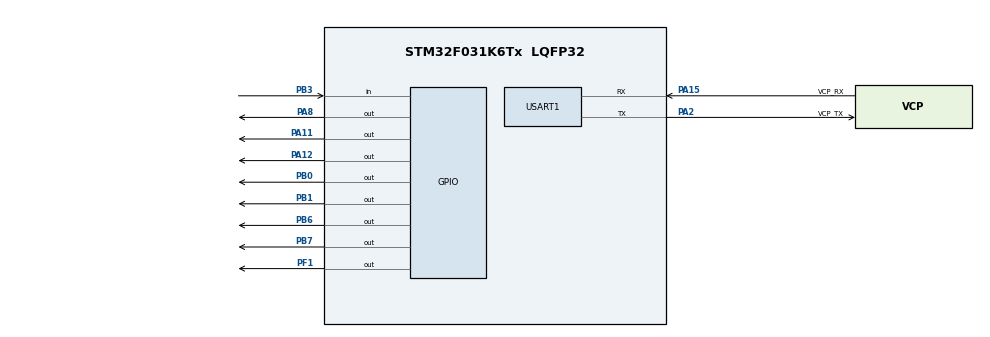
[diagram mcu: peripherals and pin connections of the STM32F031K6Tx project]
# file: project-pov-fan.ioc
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Mcu.Family=STM32F0
Mcu.Name=STM32F031K6Tx
Mcu.Package=LQFP32
PA11.Signal=GPIO_Output
PA12.Signal=GPIO_Output
PA13.GPIO_Label=SWDIO
PA13.Mode=Serial_Wire
PA13.Signal=SYS_SWDIO
PA14.GPIO_Label=SWCLK
PA14.Mode=Serial_Wire
PA14.Signal=SYS_SWCLK
PA15.GPIO_Label=VCP_RX
PA15.Mode=Asynchronous
PA15.Signal=USART1_RX
PA2.GPIO_Label=VCP_TX
PA2.Mode=Asynchronous
PA2.Signal=USART1_TX
PA8.Signal=GPIO_Output
PB0.Signal=GPIO_Output
PB1.Signal=GPIO_Output
PB3.Signal=GPIO_Input
PB6.Signal=GPIO_Output
PB7.Signal=GPIO_Output
PF0-OSC_IN.Mode=HSE-External-Clock-Source
PF0-OSC_IN.Signal=RCC_OSC_IN
PF1-OSC_OUT.Signal=GPIO_Output
ProjectManager.HeapSize=0x200
ProjectManager.StackSize=0x400
ProjectManager.TargetToolchain=STM32CubeIDE
USART1.VirtualMode-Asynchronous=VM_ASYNC
board=NUCLEO-F031K6

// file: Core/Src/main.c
/* USER CODE BEGIN Header */
/**
  ******************************************************************************
  * @file           : main.c
  * @brief          : Main program body
  ******************************************************************************
  * @attention
  *
  * Copyright (c) 2021 STMicroelectronics.
  * All rights reserved.
  *
  * This software is licensed under terms that can be found in the LICENSE file
  * in the root directory of this software component.
  * If no LICENSE file comes with this software, it is provided AS-IS.
  *
  ******************************************************************************
  */
/* USER CODE END Header */
#include "main.h"
#include "characters.h"

UART_HandleTypeDef huart1;

void SystemClock_Config(void);
static void MX_GPIO_Init(void);
static void MX_USART1_UART_Init(void);
void printLetter(int []);
void loop(void);

int main(void)
{

  /* MCU Configuration--------------------------------------------------------*/

  /* Reset of all peripherals, Initializes the Flash interface and the Systick. */
  HAL_Init();

  /* Configure the system clock */
  SystemClock_Config();

  /* Initialize all configured peripherals */
  MX_GPIO_Init();
  MX_USART1_UART_Init();

  /* Infinite loop */
  while (1)
  {

    /* USER CODE BEGIN 3 */
	  loop();
  }
  /* USER CODE END 3 */
}

void SystemClock_Config(void)
{
  RCC_OscInitTypeDef RCC_OscInitStruct = {0};
  RCC_ClkInitTypeDef RCC_ClkInitStruct = {0};
  RCC_PeriphCLKInitTypeDef PeriphClkInit = {0};

  /** Initializes the RCC Oscillators according to the specified parameters
  * in the RCC_OscInitTypeDef structure.
  */
  RCC_OscInitStruct.OscillatorType = RCC_OSCILLATORTYPE_HSI;
  RCC_OscInitStruct.HSIState = RCC_HSI_ON;
  RCC_OscInitStruct.HSICalibrationValue = RCC_HSICALIBRATION_DEFAULT;
  RCC_OscInitStruct.PLL.PLLState = RCC_PLL_NONE;
  if (HAL_RCC_OscConfig(&RCC_OscInitStruct) != HAL_OK)
  {
    Error_Handler();
  }
  /** Initializes the CPU, AHB and APB buses clocks
  */
  RCC_ClkInitStruct.ClockType = RCC_CLOCKTYPE_HCLK|RCC_CLOCKTYPE_SYSCLK
                              |RCC_CLOCKTYPE_PCLK1;
  RCC_ClkInitStruct.SYSCLKSource = RCC_SYSCLKSOURCE_HSI;
  RCC_ClkInitStruct.AHBCLKDivider = RCC_SYSCLK_DIV1;
  RCC_ClkInitStruct.APB1CLKDivider = RCC_HCLK_DIV1;

  if (HAL_RCC_ClockConfig(&RCC_ClkInitStruct, FLASH_LATENCY_0) != HAL_OK)
  {
    Error_Handler();
  }
  PeriphClkInit.PeriphClockSelection = RCC_PERIPHCLK_USART1;
  PeriphClkInit.Usart1ClockSelection = RCC_USART1CLKSOURCE_PCLK1;
  if (HAL_RCCEx_PeriphCLKConfig(&PeriphClkInit) != HAL_OK)
  {
    Error_Handler();
  }
}

static void MX_USART1_UART_Init(void)
{

  huart1.Instance = USART1;
  huart1.Init.BaudRate = 38400;
  huart1.Init.WordLength = UART_WORDLENGTH_8B;
  huart1.Init.StopBits = UART_STOPBITS_1;
  huart1.Init.Parity = UART_PARITY_NONE;
  huart1.Init.Mode = UART_MODE_TX_RX;
  huart1.Init.HwFlowCtl = UART_HWCONTROL_NONE;
  huart1.Init.OverSampling = UART_OVERSAMPLING_16;
  huart1.Init.OneBitSampling = UART_ONE_BIT_SAMPLE_DISABLE;
  huart1.AdvancedInit.AdvFeatureInit = UART_ADVFEATURE_NO_INIT;
  if (HAL_UART_Init(&huart1) != HAL_OK)
  {
    Error_Handler();
  }

}

static void MX_GPIO_Init(void)
{
  GPIO_InitTypeDef GPIO_InitStruct = {0};

  /* GPIO Ports Clock Enable */
  __HAL_RCC_GPIOF_CLK_ENABLE();
  __HAL_RCC_GPIOA_CLK_ENABLE();
  __HAL_RCC_GPIOB_CLK_ENABLE();

  /*Configure GPIO pin Output Level */
  HAL_GPIO_WritePin(GPIOF, GPIO_PIN_1, GPIO_PIN_RESET);

  /*Configure GPIO pin Output Level */
  HAL_GPIO_WritePin(GPIOB, GPIO_PIN_0|GPIO_PIN_1|GPIO_PIN_6|GPIO_PIN_7, GPIO_PIN_RESET);

  /*Configure GPIO pin Output Level */
  HAL_GPIO_WritePin(GPIOA, GPIO_PIN_8|GPIO_PIN_11|GPIO_PIN_12, GPIO_PIN_RESET);

  /*Configure GPIO pin : PF1 */
  GPIO_InitStruct.Pin = GPIO_PIN_1;
  GPIO_InitStruct.Mode = GPIO_MODE_OUTPUT_PP;
  GPIO_InitStruct.Pull = GPIO_NOPULL;
  GPIO_InitStruct.Speed = GPIO_SPEED_FREQ_LOW;
  HAL_GPIO_Init(GPIOF, &GPIO_InitStruct);

  /*Configure GPIO pins : PB0 PB1 PB6 PB7 */
  GPIO_InitStruct.Pin = GPIO_PIN_0|GPIO_PIN_1|GPIO_PIN_6|GPIO_PIN_7;
  GPIO_InitStruct.Mode = GPIO_MODE_OUTPUT_PP;
  GPIO_InitStruct.Pull = GPIO_NOPULL;
  GPIO_InitStruct.Speed = GPIO_SPEED_FREQ_LOW;
  HAL_GPIO_Init(GPIOB, &GPIO_InitStruct);

  /*Configure GPIO pins : PA8 PA11 PA12 */
  GPIO_InitStruct.Pin = GPIO_PIN_8|GPIO_PIN_11|GPIO_PIN_12;
  GPIO_InitStruct.Mode = GPIO_MODE_OUTPUT_PP;
  GPIO_InitStruct.Pull = GPIO_NOPULL;
  GPIO_InitStruct.Speed = GPIO_SPEED_FREQ_LOW;
  HAL_GPIO_Init(GPIOA, &GPIO_InitStruct);

  /*Configure GPIO pin : PB3 */
  GPIO_InitStruct.Pin = GPIO_PIN_3;
  GPIO_InitStruct.Mode = GPIO_MODE_INPUT;
  GPIO_InitStruct.Pull = GPIO_NOPULL;
  HAL_GPIO_Init(GPIOB, &GPIO_InitStruct);

}

void Error_Handler(void)
{
  __disable_irq();
  while (1)
  {
  }
}
void printLetter(int letter[])
 {
 int y;
 // printing the first y row of the letter
 for (y=0; y<8; y++)
 {
	 if(letter[y]){
		 switch(y % 8)
		 	 {
		 	 case 0:
		 		 HAL_GPIO_WritePin(GPIOA, GPIO_PIN_12, GPIO_PIN_SET);
		 		 break;
		 	 case 1:
		 		 HAL_GPIO_WritePin(GPIOB, GPIO_PIN_0, GPIO_PIN_SET);
		 		 break;
		 	 case 2:
		 		 HAL_GPIO_WritePin(GPIOB, GPIO_PIN_7, GPIO_PIN_SET);
		 		 break;
		 	 case 3:
		 		 HAL_GPIO_WritePin(GPIOB, GPIO_PIN_6, GPIO_PIN_SET);
		 		 break;
		 	 case 4:
		 		 HAL_GPIO_WritePin(GPIOB, GPIO_PIN_1, GPIO_PIN_SET);
		 		 break;
		 	 case 5:
		 		 HAL_GPIO_WritePin(GPIOF, GPIO_PIN_1, GPIO_PIN_SET);
		 		 break;
		 	 case 6:
		 		 HAL_GPIO_WritePin(GPIOA, GPIO_PIN_8, GPIO_PIN_SET);
		 		 break;
		 	 case 7:
		 		 HAL_GPIO_WritePin(GPIOF, GPIO_PIN_11, GPIO_PIN_SET);
		 		 break;
		 	 }
	 }
	 else if(!letter[y]){
		 switch(y % 8)
		 	 {
		 	 case 0:
		 		 HAL_GPIO_WritePin(GPIOA, GPIO_PIN_12, GPIO_PIN_RESET);
		 		 break;
		 	 case 1:
		 		 HAL_GPIO_WritePin(GPIOB, GPIO_PIN_0, GPIO_PIN_RESET);
		 		 break;
		 	 case 2:
		 		 HAL_GPIO_WritePin(GPIOB, GPIO_PIN_7, GPIO_PIN_RESET);
		 		 break;
		 	 case 3:
		 		 HAL_GPIO_WritePin(GPIOB, GPIO_PIN_6, GPIO_PIN_RESET);
		 		 break;
		 	 case 4:
		 		 HAL_GPIO_WritePin(GPIOB, GPIO_PIN_1, GPIO_PIN_RESET);
		 		 break;
		 	 case 5:
		 		 HAL_GPIO_WritePin(GPIOF, GPIO_PIN_1, GPIO_PIN_RESET);
		 		 break;
		 	 case 6:
		 		 HAL_GPIO_WritePin(GPIOA, GPIO_PIN_8, GPIO_PIN_RESET);
		 		 break;
		 	 case 7:
		 		 HAL_GPIO_WritePin(GPIOF, GPIO_PIN_11, GPIO_PIN_RESET);
		 		 break;
		 	 }
	 }
 }
 HAL_Delay(dotTime);
// printing the second y row of the letter
 for (y=0; y<8; y++)
 {
	 if(letter[y + 8]){
		 switch(y % 8)
		 	 {
		 	 case 0:
		 		 HAL_GPIO_WritePin(GPIOA, GPIO_PIN_12, GPIO_PIN_SET);
		 		 break;
		 	 case 1:
		 		 HAL_GPIO_WritePin(GPIOB, GPIO_PIN_0, GPIO_PIN_SET);
		 		 break;
		 	 case 2:
		 		 HAL_GPIO_WritePin(GPIOB, GPIO_PIN_7, GPIO_PIN_SET);
		 		 break;
		 	 case 3:
		 		 HAL_GPIO_WritePin(GPIOB, GPIO_PIN_6, GPIO_PIN_SET);
		 		 break;
		 	 case 4:
		 		 HAL_GPIO_WritePin(GPIOB, GPIO_PIN_1, GPIO_PIN_SET);
		 		 break;
		 	 case 5:
		 		 HAL_GPIO_WritePin(GPIOF, GPIO_PIN_1, GPIO_PIN_SET);
		 		 break;
		 	 case 6:
		 		 HAL_GPIO_WritePin(GPIOA, GPIO_PIN_8, GPIO_PIN_SET);
		 		 break;
		 	 case 7:
		 		 HAL_GPIO_WritePin(GPIOF, GPIO_PIN_11, GPIO_PIN_SET);
		 		 break;
		 	 }
	 }
	 else if(!letter[y + 8]){
		 switch(y % 8)
		 	 {
		 	 case 0:
		 		 HAL_GPIO_WritePin(GPIOA, GPIO_PIN_12, GPIO_PIN_RESET);
		 		 break;
		 	 case 1:
		 		 HAL_GPIO_WritePin(GPIOB, GPIO_PIN_0, GPIO_PIN_RESET);
		 		 break;
		 	 case 2:
		 		 HAL_GPIO_WritePin(GPIOB, GPIO_PIN_7, GPIO_PIN_RESET);
		 		 break;
		 	 case 3:
		 		 HAL_GPIO_WritePin(GPIOB, GPIO_PIN_6, GPIO_PIN_RESET);
		 		 break;
		 	 case 4:
		 		 HAL_GPIO_WritePin(GPIOB, GPIO_PIN_1, GPIO_PIN_RESET);
		 		 break;
		 	 case 5:
		 		 HAL_GPIO_WritePin(GPIOF, GPIO_PIN_1, GPIO_PIN_RESET);
		 		 break;
		 	 case 6:
		 		 HAL_GPIO_WritePin(GPIOA, GPIO_PIN_8, GPIO_PIN_RESET);
		 		 break;
		 	 case 7:
		 		 HAL_GPIO_WritePin(GPIOF, GPIO_PIN_11, GPIO_PIN_RESET);
		 		 break;
		 	 }
	 }
 }
    HAL_Delay(dotTime);
// printing the third y row of the letter
 for (y=0; y<8; y++)
 {
	 if(letter[y + 16]){
		 switch(y % 8)
		 	 {
		 	 case 0:
		 		 HAL_GPIO_WritePin(GPIOA, GPIO_PIN_12, GPIO_PIN_SET);
		 		 break;
		 	 case 1:
		 		 HAL_GPIO_WritePin(GPIOB, GPIO_PIN_0, GPIO_PIN_SET);
		 		 break;
		 	 case 2:
		 		 HAL_GPIO_WritePin(GPIOB, GPIO_PIN_7, GPIO_PIN_SET);
		 		 break;
		 	 case 3:
		 		 HAL_GPIO_WritePin(GPIOB, GPIO_PIN_6, GPIO_PIN_SET);
		 		 break;
		 	 case 4:
		 		 HAL_GPIO_WritePin(GPIOB, GPIO_PIN_1, GPIO_PIN_SET);
		 		 break;
		 	 case 5:
		 		 HAL_GPIO_WritePin(GPIOF, GPIO_PIN_1, GPIO_PIN_SET);
		 		 break;
		 	 case 6:
		 		 HAL_GPIO_WritePin(GPIOA, GPIO_PIN_8, GPIO_PIN_SET);
		 		 break;
		 	 case 7:
		 		 HAL_GPIO_WritePin(GPIOF, GPIO_PIN_11, GPIO_PIN_SET);
		 		 break;
		 	 }
	 }
	 else if(!letter[y + 16]){
		 switch(y % 8)
		 	 {
		 	 case 0:
		 		 HAL_GPIO_WritePin(GPIOA, GPIO_PIN_12, GPIO_PIN_RESET);
		 		 break;
		 	 case 1:
		 		 HAL_GPIO_WritePin(GPIOB, GPIO_PIN_0, GPIO_PIN_RESET);
		 		 break;
		 	 case 2:
		 		 HAL_GPIO_WritePin(GPIOB, GPIO_PIN_7, GPIO_PIN_RESET);
		 		 break;
		 	 case 3:
		 		 HAL_GPIO_WritePin(GPIOB, GPIO_PIN_6, GPIO_PIN_RESET);
		 		 break;
		 	 case 4:
		 		 HAL_GPIO_WritePin(GPIOB, GPIO_PIN_1, GPIO_PIN_RESET);
		 		 break;
		 	 case 5:
		 		 HAL_GPIO_WritePin(GPIOF, GPIO_PIN_1, GPIO_PIN_RESET);
		 		 break;
		 	 case 6:
		 		 HAL_GPIO_WritePin(GPIOA, GPIO_PIN_8, GPIO_PIN_RESET);
		 		 break;
		 	 case 7:
		 		 HAL_GPIO_WritePin(GPIOF, GPIO_PIN_11, GPIO_PIN_RESET);
		 		 break;
		 	 }
	 }
 }
    HAL_Delay(dotTime);
 for(y = 0; y<8; y++)
    {
	 if(letter[y + 24]){
		 switch(y % 8)
		 	 {
		 	 case 0:
		 		 HAL_GPIO_WritePin(GPIOA, GPIO_PIN_12, GPIO_PIN_SET);
		 		 break;
		 	 case 1:
		 		 HAL_GPIO_WritePin(GPIOB, GPIO_PIN_0, GPIO_PIN_SET);
		 		 break;
		 	 case 2:
		 		 HAL_GPIO_WritePin(GPIOB, GPIO_PIN_7, GPIO_PIN_SET);
		 		 break;
		 	 case 3:
		 		 HAL_GPIO_WritePin(GPIOB, GPIO_PIN_6, GPIO_PIN_SET);
		 		 break;
		 	 case 4:
		 		 HAL_GPIO_WritePin(GPIOB, GPIO_PIN_1, GPIO_PIN_SET);
		 		 break;
		 	 case 5:
		 		 HAL_GPIO_WritePin(GPIOF, GPIO_PIN_1, GPIO_PIN_SET);
		 		 break;
		 	 case 6:
		 		 HAL_GPIO_WritePin(GPIOA, GPIO_PIN_8, GPIO_PIN_SET);
		 		 break;
		 	 case 7:
		 		 HAL_GPIO_WritePin(GPIOF, GPIO_PIN_11, GPIO_PIN_SET);
		 		 break;
		 	 }
	 }
	 else if(!letter[y + 24]){
		 switch(y % 8)
		 	 {
		 	 case 0:
		 		 HAL_GPIO_WritePin(GPIOA, GPIO_PIN_12, GPIO_PIN_RESET);
		 		 break;
		 	 case 1:
		 		 HAL_GPIO_WritePin(GPIOB, GPIO_PIN_0, GPIO_PIN_RESET);
		 		 break;
		 	 case 2:
		 		 HAL_GPIO_WritePin(GPIOB, GPIO_PIN_7, GPIO_PIN_RESET);
		 		 break;
		 	 case 3:
		 		 HAL_GPIO_WritePin(GPIOB, GPIO_PIN_6, GPIO_PIN_RESET);
		 		 break;
		 	 case 4:
		 		 HAL_GPIO_WritePin(GPIOB, GPIO_PIN_1, GPIO_PIN_RESET);
		 		 break;
		 	 case 5:
		 		 HAL_GPIO_WritePin(GPIOF, GPIO_PIN_1, GPIO_PIN_RESET);
		 		 break;
		 	 case 6:
		 		 HAL_GPIO_WritePin(GPIOA, GPIO_PIN_8, GPIO_PIN_RESET);
		 		 break;
		 	 case 7:
		 		 HAL_GPIO_WritePin(GPIOF, GPIO_PIN_11, GPIO_PIN_RESET);
		 		 break;
		 	 }
	 }
    }
 	 HAL_Delay(dotTime);
for(y = 0; y<8; y++)
    {
	 if(letter[y + 32]){
		 switch(y % 8)
		 	 {
		 	 case 0:
		 		 HAL_GPIO_WritePin(GPIOA, GPIO_PIN_12, GPIO_PIN_SET);
		 		 break;
		 	 case 1:
		 		 HAL_GPIO_WritePin(GPIOB, GPIO_PIN_0, GPIO_PIN_SET);
		 		 break;
		 	 case 2:
		 		 HAL_GPIO_WritePin(GPIOB, GPIO_PIN_7, GPIO_PIN_SET);
		 		 break;
		 	 case 3:
		 		 HAL_GPIO_WritePin(GPIOB, GPIO_PIN_6, GPIO_PIN_SET);
		 		 break;
		 	 case 4:
		 		 HAL_GPIO_WritePin(GPIOB, GPIO_PIN_1, GPIO_PIN_SET);
		 		 break;
		 	 case 5:
		 		 HAL_GPIO_WritePin(GPIOF, GPIO_PIN_1, GPIO_PIN_SET);
		 		 break;
		 	 case 6:
		 		 HAL_GPIO_WritePin(GPIOA, GPIO_PIN_8, GPIO_PIN_SET);
		 		 break;
		 	 case 7:
		 		 HAL_GPIO_WritePin(GPIOF, GPIO_PIN_11, GPIO_PIN_SET);
		 		 break;
		 	 }
	 }
	 else if(!letter[y + 32]){
		 switch(y % 8)
		 	 {
		 	 case 0:
		 		 HAL_GPIO_WritePin(GPIOA, GPIO_PIN_12, GPIO_PIN_RESET);
		 		 break;
		 	 case 1:
		 		 HAL_GPIO_WritePin(GPIOB, GPIO_PIN_0, GPIO_PIN_RESET);
		 		 break;
		 	 case 2:
		 		 HAL_GPIO_WritePin(GPIOB, GPIO_PIN_7, GPIO_PIN_RESET);
		 		 break;
		 	 case 3:
		 		 HAL_GPIO_WritePin(GPIOB, GPIO_PIN_6, GPIO_PIN_RESET);
		 		 break;
		 	 case 4:
		 		 HAL_GPIO_WritePin(GPIOB, GPIO_PIN_1, GPIO_PIN_RESET);
		 		 break;
		 	 case 5:
		 		 HAL_GPIO_WritePin(GPIOF, GPIO_PIN_1, GPIO_PIN_RESET);
		 		 break;
		 	 case 6:
		 		 HAL_GPIO_WritePin(GPIOA, GPIO_PIN_8, GPIO_PIN_RESET);
		 		 break;
		 	 case 7:
		 		 HAL_GPIO_WritePin(GPIOF, GPIO_PIN_11, GPIO_PIN_RESET);
		 		 break;
		 	 }
	 }
    }
  	  HAL_Delay(dotTime);
 // printing the space between the letters
 for (y=0; y<8; y++)
 {
	 HAL_GPIO_WritePin(GPIOA, GPIO_PIN_12, GPIO_PIN_RESET);
	 HAL_GPIO_WritePin(GPIOB, GPIO_PIN_0, GPIO_PIN_RESET);
	 HAL_GPIO_WritePin(GPIOB, GPIO_PIN_7, GPIO_PIN_RESET);
	 HAL_GPIO_WritePin(GPIOB, GPIO_PIN_6, GPIO_PIN_RESET);
	 HAL_GPIO_WritePin(GPIOB, GPIO_PIN_1, GPIO_PIN_RESET);
	 HAL_GPIO_WritePin(GPIOF, GPIO_PIN_1, GPIO_PIN_RESET);
	 HAL_GPIO_WritePin(GPIOA, GPIO_PIN_8, GPIO_PIN_RESET);
	 HAL_GPIO_WritePin(GPIOF, GPIO_PIN_11, GPIO_PIN_RESET);
 }
 	 HAL_Delay(0.006);
 }

void loop()//write here =)
 {
 printLetter (H);
 printLetter (E);
 printLetter (L);
 printLetter (L);
 printLetter (O);
 printLetter (_);
 printLetter (A);
 printLetter (L);
 printLetter (L);
}
